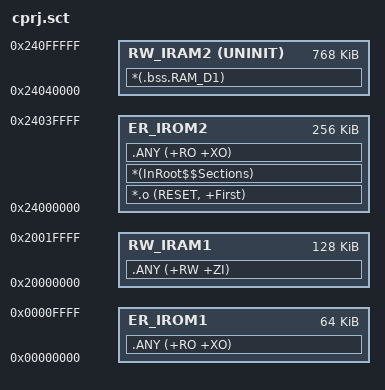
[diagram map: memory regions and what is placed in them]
; *************************************************************
; *** Scatter-Loading Description File generated by uVision ***
; *************************************************************

LR_IROM2 0x24000000 0x00040000  {    ; load region size_region
  ER_IROM2 0x24000000 0x00040000  {  ; load address = execution address
   *.o (RESET, +First)
   *(InRoot$$Sections)
   .ANY (+RO +XO)
  }
  RW_IRAM1 0x20000000 0x00020000  {
   .ANY (+RW +ZI)
  }
  RW_IRAM2 0x24040000 UNINIT 0x000C0000  {
   *(.bss.RAM_D1)
  }
}

LR_IROM1 0x00000000 0x00010000  {
  ER_IROM1 0x00000000 0x00010000  {  ; load address = execution address
   .ANY (+RO +XO)
  }
}
